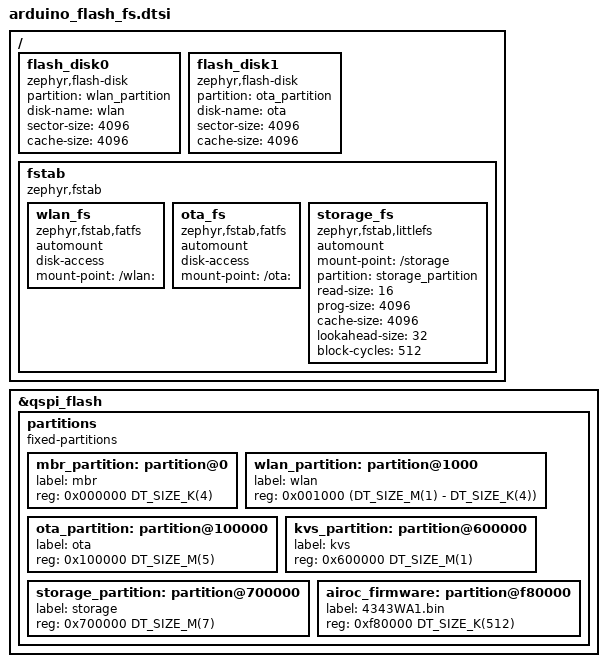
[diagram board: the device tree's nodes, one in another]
/*
 * Copyright (c) Arduino s.r.l. and/or its affiliated companies
 *
 * SPDX-License-Identifier: Apache-2.0
 */

/*
 * Common filesystem configuration
 *
 * This file defines the following:
 *
 * 1- Common partition layout for 16MB flash:
 * - mbr: 4KB @ 0x000000 (Master Boot Record - protected)
 * - wlan: ~1020KB @ 0x001000 (Network certificates)
 * - ota: 5MB @ 0x100000 (OTA updates)
 * - kvs: 1MB @ 0x600000 (Key-Value Store)
 * - storage: 7MB @ 0x700000 (User data)
 *
 * 2- fstab entries and flash-disk devices for:
 * - /wlan: (FAT) - Network certificates partition
 * - /ota: (FAT) - OTA update partition
 * - /storage (LittleFS) - User data partition
 */

&qspi_flash {
	/delete-node/ partitions;
	partitions {
		compatible = "fixed-partitions";
		#address-cells = <1>;
		#size-cells = <1>;

		mbr_partition: partition@0 {
			label = "mbr";
			reg = <0x000000 DT_SIZE_K(4)>;
		};

		/* Partition 1: Network certificates 1MB - 4KB (MBR reserved at 0x0) */
		wlan_partition: partition@1000 {
			label = "wlan";
			reg = <0x001000 (DT_SIZE_M(1) - DT_SIZE_K(4))>;
		};

		/* Partition 2: OTA 5MB */
		ota_partition: partition@100000 {
			label = "ota";
			reg = <0x100000 DT_SIZE_M(5)>;
		};

		/* Partition 3: Provisioning KVStore 1MB */
		kvs_partition: partition@600000 {
			label = "kvs";
			reg = <0x600000 DT_SIZE_M(1)>;
		};

		/* Partition 4: User data 7MB */
		storage_partition: partition@700000 {
			label = "storage";
			reg = <0x700000 DT_SIZE_M(7)>;
		};

		/* Partition 5: Binary FW image for the Airoc WLAN */
		airoc_firmware: partition@f80000 {
			label = "4343WA1.bin";
			reg = <0xf80000 DT_SIZE_K(512)>;
		};
	};
};

/ {
	flash_disk0 {
		status = "okay";
		compatible = "zephyr,flash-disk";
		partition = <&wlan_partition>;
		disk-name = "wlan";
		sector-size = <4096>;
		cache-size = <4096>;
	};

	flash_disk1 {
		status = "okay";
		compatible = "zephyr,flash-disk";
		partition = <&ota_partition>;
		disk-name = "ota";
		sector-size = <4096>;
		cache-size = <4096>;
	};

	fstab {
		compatible = "zephyr,fstab";

		wlan_fs: wlan_fs {
			compatible = "zephyr,fstab,fatfs";
			automount;
			disk-access;
			mount-point = "/wlan:";
		};

		ota_fs: ota_fs {
			compatible = "zephyr,fstab,fatfs";
			automount;
			disk-access;
			mount-point = "/ota:";
		};

		storage_fs: storage_fs {
			compatible = "zephyr,fstab,littlefs";
			automount;
			mount-point = "/storage";
			partition = <&storage_partition>;
			read-size = <16>;
			prog-size = <4096>;
			cache-size = <4096>;
			lookahead-size = <32>;
			block-cycles = <512>;
		};
	};
};
